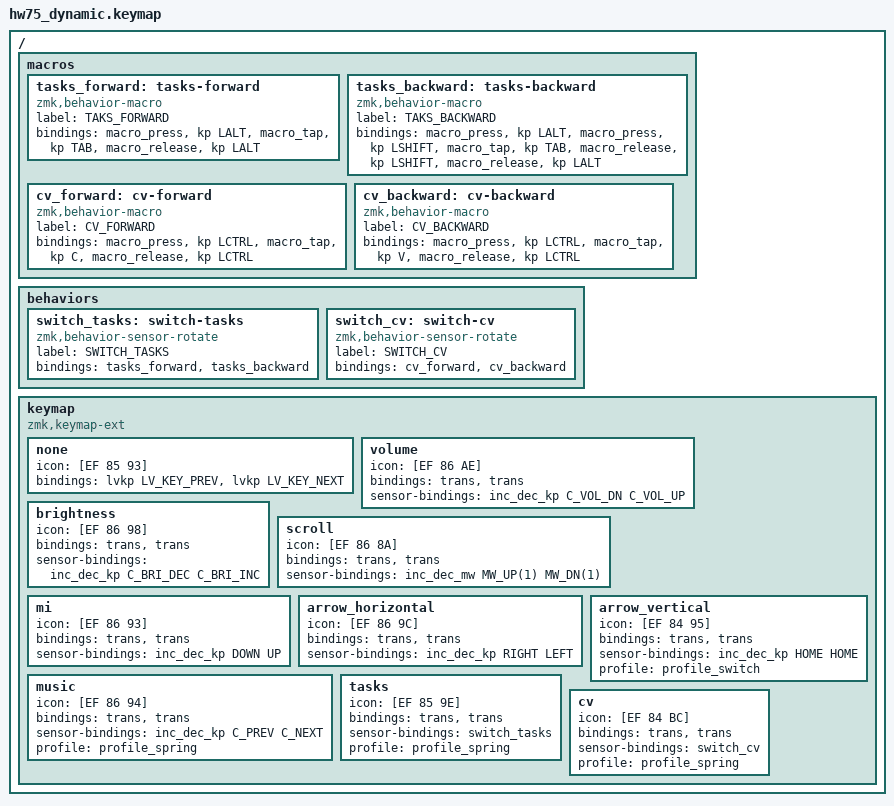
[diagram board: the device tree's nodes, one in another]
/*
 * Copyright (c) 2022 The ZMK Contributors
 * SPDX-License-Identifier: MIT
 */

#include <behaviors.dtsi>
#include <behaviors/lvgl_key_press.dtsi>
#include <behaviors/sensor_rotate_mouse_wheel.dtsi>
#include <dt-bindings/zmk/keys.h>
#include <dt-bindings/zmk/rgb.h>
#include <dt-bindings/zmk/lvgl.h>
#include <dt-bindings/zmk/mouse.h>

/ {
	macros {
		tasks_forward: tasks-forward {
			label = "TAKS_FORWARD";
			compatible = "zmk,behavior-macro";
			#binding-cells = <0>;
			bindings = <&macro_press   &kp LALT>,
				   <&macro_tap     &kp TAB>,
				   <&macro_release &kp LALT>;
		};

		tasks_backward: tasks-backward {
			label = "TAKS_BACKWARD";
			compatible = "zmk,behavior-macro";
			#binding-cells = <0>;
			bindings = <&macro_press   &kp LALT>,
				   <&macro_press   &kp LSHIFT>,
				   <&macro_tap     &kp TAB>,
				   <&macro_release &kp LSHIFT>,
				   <&macro_release &kp LALT>;
		};

                cv_forward: cv-forward {
			label = "CV_FORWARD";
			compatible = "zmk,behavior-macro";
			#binding-cells = <0>;
			bindings = <&macro_press   &kp LCTRL>,
				   <&macro_tap     &kp C>,
				   <&macro_release &kp LCTRL>;
		};

                cv_backward: cv-backward {
			label = "CV_BACKWARD";
			compatible = "zmk,behavior-macro";
			#binding-cells = <0>;
			bindings = <&macro_press   &kp LCTRL>,
				   <&macro_tap     &kp V>,
				   <&macro_release &kp LCTRL>;
 		};
	};

	behaviors {
		switch_tasks: switch-tasks {
			compatible = "zmk,behavior-sensor-rotate";
			label = "SWITCH_TASKS";
			#sensor-binding-cells = <0>;
			bindings = <&tasks_forward>, <&tasks_backward>;
		};

                switch_cv: switch-cv {
			compatible = "zmk,behavior-sensor-rotate";
			label = "SWITCH_CV";
			#sensor-binding-cells = <0>;
			bindings = <&cv_forward>, <&cv_backward>;
		};
	};

	keymap {
		compatible = "zmk,keymap-ext", "zmk,keymap";

                none {
			label = "摸鱼";
			icon = [EF 85 93];
			bindings = <&lvkp LV_KEY_PREV &lvkp LV_KEY_NEXT>;
		};		
                
                volume {
			label = "音量";
			icon = [EF 86 AE];
			bindings = <&trans &trans>;
			sensor-bindings = <&inc_dec_kp C_VOL_DN C_VOL_UP>;
		};

                brightness {
			label = "亮度";
			icon = [EF 86 98];
			bindings = <&trans &trans>;
			sensor-bindings = <&inc_dec_kp C_BRI_DEC C_BRI_INC>;
		};

		scroll {
			label = "滚动";
			icon = [EF 86 8A];
			bindings = <&trans &trans>;
			sensor-bindings = <&inc_dec_mw MW_UP(1) MW_DN(1)>;
		};

                mi {
			label = "上下";
			icon = [EF 86 93];
			bindings = <&trans &trans>;
			sensor-bindings = <&inc_dec_kp DOWN UP>;
		};

		arrow_horizontal {
			label = "左右";
			icon = [EF 86 9C];
			bindings = <&trans &trans>;
			sensor-bindings = <&inc_dec_kp RIGHT LEFT>;
		};

                music {
			label = "音乐";
			icon = [EF 86 94];
			bindings = <&trans &trans>;
			sensor-bindings = <&inc_dec_kp C_PREV C_NEXT>;
                        profile = <&profile_spring>;
		};

                arrow_vertical {
			label = "麦克";
			icon = [EF 84 95];
			bindings = <&trans &trans>;
			sensor-bindings = <&inc_dec_kp HOME HOME>;
                        profile = <&profile_switch>;
		};

                tasks {
			label = "窗口";
			icon = [EF 85 9E];
			bindings = <&trans &trans>;
			sensor-bindings = <&switch_tasks>;
			profile = <&profile_spring>;
                };
 
                cv {
			label = "复粘";
			icon = [EF 84 BC];
			bindings = <&trans &trans>;
			sensor-bindings = <&switch_cv>;
			profile = <&profile_spring>;
		};
	};
};
